# TA_SMS register map
Vendor: Texas Instruments
Peripheral module from a debugger description file (folder omap36xx).
Registers are 64-bit, read-only, reset 0x0 unless marked. A register's access mark holds for its fields unless they carry their own. Offsets are as the file gives them; lines under a group give offsets from that group; [hi:lo] are bit positions; {n}, {i} and the like mark numbered series; 'fields as' and 'values as' point back to an identical list; <NAME> marks a mode.

## TA_SMS
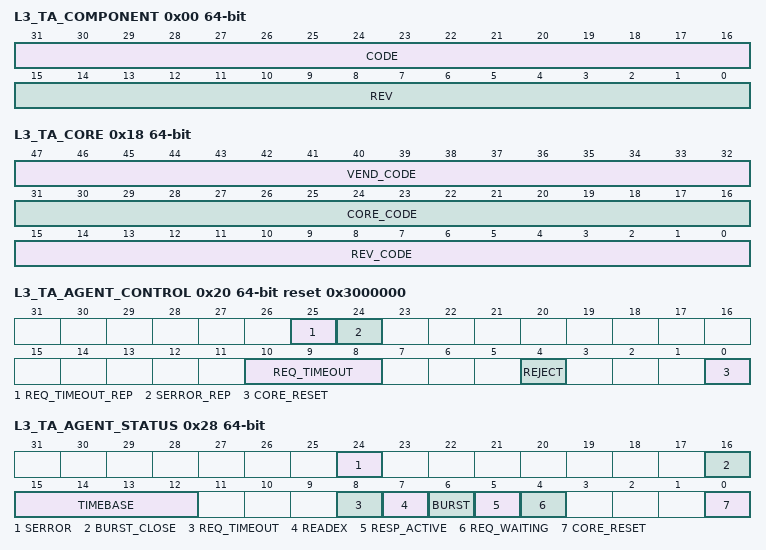
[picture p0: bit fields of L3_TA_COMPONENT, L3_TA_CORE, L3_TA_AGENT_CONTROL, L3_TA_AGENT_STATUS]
0x00 L3_TA_COMPONENT (reset mask 0xFFFFFFFF00000000) — Component register of target agent
  [31:16] CODE — Component Code
  [15:0] REV — Revision of the component
0x18 L3_TA_CORE (reset mask 0xFFFF000000000000) — Core register of Target Agent
  [47:32] VEND_CODE — Vendor Code
  [31:16] CORE_CODE
  [15:0] REV_CODE — Revision Code
0x20 L3_TA_AGENT_CONTROL access per field reset 0x3000000 — Agent control register of TA block.
  [25] REQ_TIMEOUT_REP rw — Request Timeout Reporting
    0=No special reporting; 1=Report out of band
  [24] SERROR_REP rw — SError reportingReserved for all instances except 2 (GPMC) and 6 (SGX) Reserved R 0x0000 .
    0=Suppress Serror reporting; 1=Report Serror
  [10:8] REQ_TIMEOUT rw — Request Timeout Bound:
    0=No timeout; 1=1x base cycles; 2=4x base cycles; 3=16x base cycles; 4=64x base cycles
  [4] REJECT rw — Request rejection control
    0=Request rejection control; 1=Block requests to this target
  [0] CORE_RESET rw — Reset output on core
    0=Inactive; 1=Reset control active
0x28 L3_TA_AGENT_STATUS access per field — Agent Status Register.
  [24] SERROR rw — Serror assertion detectedReserved for all instances except 2 (GPMC) and 6 (SGX) Reserved R 0 .
  [16] BURST_CLOSE ro — Forced burst close status
    0=BURST_CLOSE_0_r (Normal operation); 1=BURST_CLOSE_1_r (Burst close command)
  [15:12] TIMEBASE ro — Observation of timebase signals.
  [8] REQ_TIMEOUT ro — Request timeout status
    0=REQ_TIMEOUT_0_r (Normal operation); 1=REQ_TIMEOUT_1_r (Request timed out, responding ERR to all the requests)
  [7] READEX ro — Status of readEx/Write
    0=READEX_0_r (No pending ReadEx); 1=READEX_1_r (ReadEx pending on at lease one thread)
  [6] BURST ro — Status of open burst
    0=BURST_0_r (No open burst); 1=BURST_1_r (Open burst on at least one thread)
  [5] RESP_ACTIVE ro — Responses outstanding
    0=RESP_ACTIVE_0_r (No responses outstanding); 1=RESP_ACTIVE_1_r (Response outstanding in the target)
  [4] REQ_WAITING ro — Requests waiting
    0=REQ_WAITING_0_r (No request waiting); 1=REQ_WAITING_1_r (Request waiting for acceptance by target)
  [0] CORE_RESET ro — Reset input from core interface
    0=CORE_RESET_0_r (Reset inactive); 1=CORE_RESET_1_r (Reset active)
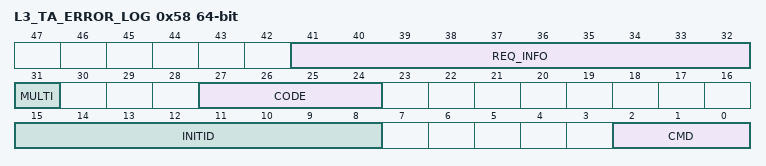
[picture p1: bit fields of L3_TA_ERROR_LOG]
0x58 L3_TA_ERROR_LOG access per field — Error log register of TA block - logs error detected by a target agent.
  [41:32] REQ_INFO ro — MReqInfo bits of command that caused the error
  [31] MULTI rw — Multiple Errors
    0=MULTI_0_w (Ignored); 0=MULTI_0_r (Multiple error not seen); 1=MULTI_1_w (Clear MULTI flag); 1=MULTI_1_r (Multiple error seen)
  [27:24] CODE rw — Error code
  [15:8] INITID ro — Initiator ID from which command was launched. . See.
  [2:0] CMD ro — Command that caused the error
0x60 L3_TA_ERROR_LOG_ADDR — Error log address register of TA block
  [31:0] ADDR — Address of the command that caused the error
